AUTOSAR XML (schema 4-2-2)
package /SensorActuator_ADC
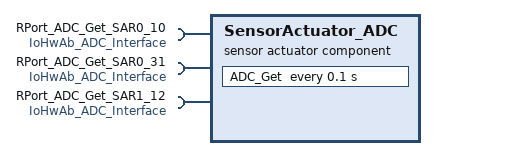
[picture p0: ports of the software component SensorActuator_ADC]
  sensor actuator sw component type SensorActuator_ADC
    require port RPort_ADC_Get_SAR0_10: required-interface=IoHwAb_ADC_Interface
    require port RPort_ADC_Get_SAR0_31: required-interface=IoHwAb_ADC_Interface
    require port RPort_ADC_Get_SAR1_12: required-interface=IoHwAb_ADC_Interface
    behavior IB_SensorActuator_ADC
      timing event TimingEvent_0: start-on-event=ADC_Get, period=0.1
      runnable ADC_Get: symbol=ADC_Get_func
        sync call SynchronousServerCallPoint_0: operation=RPort_ADC_Get_SAR0_10.IoHwAb_ADC_Get
        sync call SynchronousServerCallPoint_1: operation=RPort_ADC_Get_SAR1_12.IoHwAb_ADC_Get
        sync call SynchronousServerCallPoint_2: operation=RPort_ADC_Get_SAR0_31.IoHwAb_ADC_Get
